# psc3_p8_ppca register map
Vendor: Infineon Technologies; Series: PSC3_P8; File version: 1.0
CPU: CM33 r0p1, little endian, MPU, FPU, DSP, VTOR, 3 interrupt priority bits, 143 interrupts
Registers are 32-bit, read-write, reset 0x0 unless marked. A register's access mark holds for its fields unless they carry their own. Offsets are from the block's base; [hi:lo] are bit positions; lines under a group give offsets from that group; {n}, {i} and the like mark numbered series.

## PROMC — Patchable ROM Controller
Base 0x68140000
0x00 CTL — Control
  [1:0] ROM_WS — Wait states.
    {v}=WS_{v} (N/A) (v=0..3)
0x1000 MPC group — MPC Memory Protection Controller registers
  0x00 CFG — Config register with error response, RegionID PPC_MPC_MAIN is the security owner PC. The error response configuration is located in CFG.RESPONSE, only one such configuration exists applying to all protection contexts in the system.
    [4] RESPONSE — Response Configuration for Security and PC violations 0: Read-Zero Write Ignore (RAZ/WI) 1: Bus Error
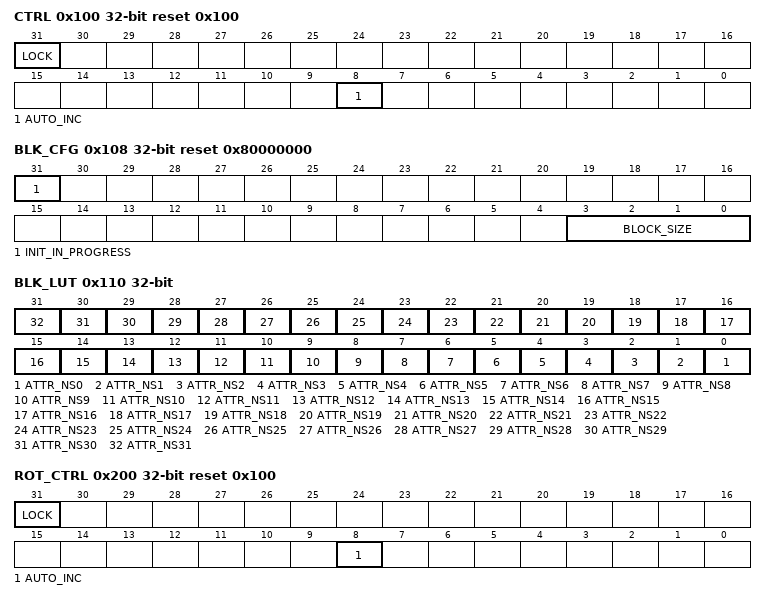
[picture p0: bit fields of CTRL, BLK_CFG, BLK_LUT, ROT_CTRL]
  0x100 CTRL reset 0x100 — Control register with lock bit and auto-increment only (Separate CTRL for each PC depends on access_pc)
    [31] LOCK write-1-sets — Security lockdown for this protection context. Software can set this bit but not clear it once set. When set, write operations to BLK_LUT are not possible from this protection context. Setting LOCK also blocks writes to CTRL itself (for that PC copy). All writes are ignored.
    [8] AUTO_INC — Auto-increment BLK_IDX by 1 for this protection context as a side effect of each read/write access to BLK_LUT
  0x104 BLK_MAX ro — Max value of block-based index register
    [31:0] VALUE — Maximum value of block-based index register. The number and size blocks in an MPC is design time configurable and for embedded memories defaults to covering the entire memory using 4kB blocks; See product datasheet for details on protection of external memories.
  0x108 BLK_CFG ro reset 0x80000000 — Block size & initialization in progress
    [31] INIT_IN_PROGRESS — During initialization INIT_IN_PROGRESS is '1' and MMIO register accesses to BLK_LUT is blocked (BLK_IDX increment is also ignored). The block attributes are retained in DeepSleep (and obviously Active) power mode. Initialization is only required from a power mode in which the block attributes are not retained. E.g., initialization is required for a cold boot (after a Power-on-Reset). HW initializes the block attributes: the NS attributes are set to '0' (secure), the R attributes are set to '1' (read access allowed) and the W attributes are set to '1' (write access allowed). During initialization, the MPC supports memory accesses (memory accesses are NOT blocked) with the initialization block attribute values as mentioned above. This e.g. allows MPC initialization to proceed in parallel with boot program memory accesses (as opposed to serializing the two), improving device boot time.
    [3:0] BLOCK_SIZE — Block size of individually protected blocks (0: 32B, 1: 64B, ... up to 15: 1MB) Block size= (1<<(BLOCK_SIZE+5)) The number and size blocks in an MPC is design time configurable and for embedded memories defaults to covering the entire memory using 4kB blocks; see product datasheet for details on protection of external memories.
  0x10C BLK_IDX — Index of 32-block group accessed through BLK_LUT (Separate IDX for each PC depending on access_pc)
    [31:0] VALUE — Index value for accessing block-based lookup table using BLK_LUT. Programming out of LUT range is an user error and it loops back to '0' once overflow occurs.
  0x110 BLK_LUT — NS status for 32 blocks at BLK_IDX with PC=<access_pc>
    [n] ATTR_NS{n} (n=0..31) — NS bit for block {n} based on BLK_IDX
  0x200 ROT_CTRL reset 0x100 — Control register with lock bit and auto-increment only
    [31] LOCK write-1-sets — Security lockdown for the root-of-trust configuration registers. Software can set this bit but not clear it once set. When set, write operations to ROT_BLK_LUT are not possible. Write is ignored.
    [8] AUTO_INC — Auto-increment ROT_BLK_IDX by 1 for each read/write of ROT_BLK_LUT
  0x208 ROT_BLK_MAX ro — Max value of block-based index register for ROT
    [31:0] VALUE — Maximum value of block-based index register. The number and size blocks in an MPC is design time configurable and for embedded memories defaults to covering the entire memory using 4kB blocks; see product datasheet for details on protection of external memories.
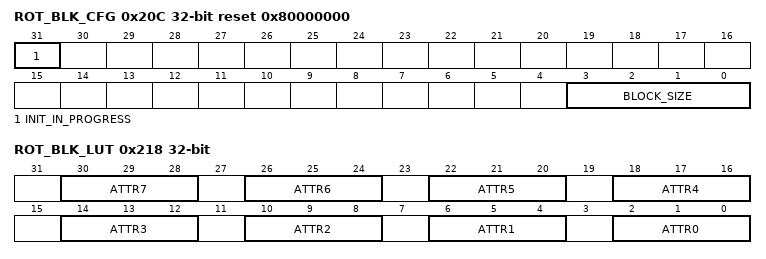
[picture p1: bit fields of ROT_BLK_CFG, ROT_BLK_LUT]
  0x20C ROT_BLK_CFG ro reset 0x80000000 — Same as BLK_CFG
    [31] INIT_IN_PROGRESS — During initialization INIT_IN_PROGRESS is '1' and MMIO register accesses to ROT_BLK_LUT is RAZWI. The block attributes are retained in DeepSleep (and obviously Active) power mode. Initialization is only required from a power mode in which the block attributes are not retained. E.g., initialization is required for a cold boot (after a Power-on-Reset). HW initializes the block attributes: the NS attributes are set to '0' (secure), the R attributes are set to '1' (read access allowed) and the W attributes are set to '1' (write access allowed). During initialization, the MPC supports memory accesses (memory accesses are NOT blocked) with the initialization block attribute values as mentioned above. This e.g. allows MPC initialization to proceed in parallel with boot program memory accesses (as opposed to serializing the two), improving device boot time.
    [3:0] BLOCK_SIZE — Block size of individually protected blocks (0: 32B, 1: 64B, ...up to 15:1MB) Block size= (1<<(BLOCK_SIZE+5)) The number and size blocks in an MPC is design time configurable and for embedded memories defaults to covering the entire memory using 4kB blocks; see product datasheet for details on protection of external memories.
  0x210 ROT_BLK_IDX — Index of 8-block group accessed through ROT_BLK_LUT_*
    [31:0] VALUE — Index value for accessing block-based lookup table using ROT_BLK_LUT. Programming out of LUT range is an user error and it loops back to '0' once overflow occurs.
  0x214 ROT_BLK_PC — Protection context of 8-block group accesses through ROT_BLK_LUT
    [3:0] PC — Specify PC values for ROT_BLK_IDX and ROT_BLK_LUT
  0x218 ROT_BLK_LUT — (R,W,NS) bits for 8 blocks at ROT_BLK_IDX for PC=ROT_BKL_PC
    [4n+2:4n] ATTR{n} (n=0..7) — W/R/NS bits for block {n} indicated by ROT_BLK_IDX for ROT_BLK_PC PC
